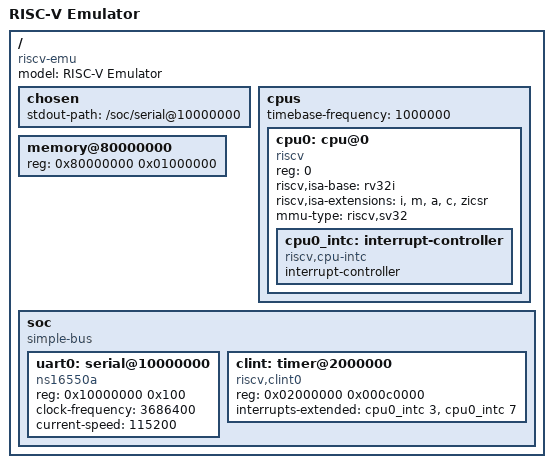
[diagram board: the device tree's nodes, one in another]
/dts-v1/;

/ {
    compatible = "riscv-emu";
    model = "RISC-V Emulator";

    #address-cells = <1>;
    #size-cells = <1>;

    chosen {
        stdout-path = "/soc/serial@10000000";
    };

    cpus {
        #address-cells = <1>;
        #size-cells = <0>;
        timebase-frequency = <1000000>;

        cpu0: cpu@0 {
            device_type = "cpu";
            reg = <0>;
            status = "okay";
            compatible = "riscv";
            riscv,isa-base = "rv32i";
            riscv,isa-extensions = "i", "m", "a", "c", "zicsr";
            mmu-type = "riscv,sv32";

            cpu0_intc: interrupt-controller {
                compatible = "riscv,cpu-intc";
                interrupt-controller;
                #interrupt-cells = <1>;
            };
        };
    };

    memory@80000000 {
        device_type = "memory";
        reg = <0x80000000 0x01000000>;
    };

    soc {
        compatible = "simple-bus";
        #address-cells = <1>;
        #size-cells = <1>;
        ranges;

        uart0: serial@10000000 {
            compatible = "ns16550a";
            reg = <0x10000000 0x100>;
            clock-frequency = <3686400>;
            current-speed = <115200>;
        };

        clint: timer@2000000 {
            compatible = "riscv,clint0";
            reg = <0x02000000 0x000c0000>;
            interrupts-extended =
                <&cpu0_intc 3 &cpu0_intc 7>;
        };
    };
};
